AUTOSAR XML (schema 00044)
package /ComponentTypes
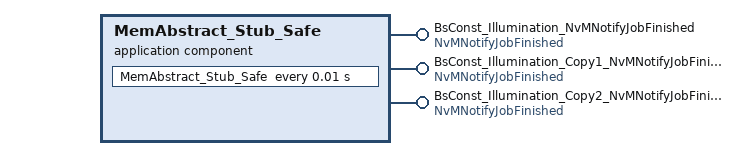
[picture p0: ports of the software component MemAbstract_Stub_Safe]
  application sw component type MemAbstract_Stub_Safe
    11 x provide/require port, all with nv-provide-com-spec=Value, nv-require-com-spec=Value:
      BsConst_BsConst_Illumination_ReservedByte: provided-required-interface=BsConst_BsConst_Illumination_ReservedByte
      BsConst_Compensation_Line_Shift_b: provided-required-interface=BsConst_Compensation_Line_Shift_b
      BsConst_Compensation_Line_Slope_m: provided-required-interface=BsConst_Compensation_Line_Slope_m
      BsConst_Derating_Backlight_Disable: provided-required-interface=BsConst_Derating_Backlight_Disable
      BsConst_Display_Illum_Max_Level_Safe: provided-required-interface=BsConst_Display_Illum_Max_Level
      BsConst_Lookup_Curve_HotSpot_Coef_X: provided-required-interface=BsConst_Lookup_Curve_HotSpot_Coef_X
      BsConst_Lookup_Curve_HotSpot_Coef_Y: provided-required-interface=BsConst_Lookup_Curve_HotSpot_Coef_Y
      BsConst_PCB_Temperature_Sensor_Conv: provided-required-interface=BsConst_PCB_Temperature_Sensor_Conv
      BsConst_PWM_boost_bypass_duty: provided-required-interface=BsConst_PWM_boost_bypass_duty
      BsConst_Temp_Threshold_Hysteresis_Derating: provided-required-interface=BsConst_Temp_Threshold_Hysteresis_Derating
      BsConst_Temperature_Sensor_Conv: provided-required-interface=BsConst_Temperature_Sensor_Conv
    provide port BsConst_Illumination_NvMNotifyJobFinished: server-com-spec{operation=JobFinished, queue-length=1}, provided-interface=NvMNotifyJobFinished
    provide port BsConst_Illumination_Copy1_NvMNotifyJobFinished: server-com-spec{operation=JobFinished, queue-length=1}, provided-interface=NvMNotifyJobFinished
    provide port BsConst_Illumination_Copy2_NvMNotifyJobFinished: server-com-spec{operation=JobFinished, queue-length=1}, provided-interface=NvMNotifyJobFinished
    behavior MemAbstract_Stub_Safe_InternalBehavior
      timing event TMT_MemAbstract_Stub_Safe: start-on-event=MemAbstract_Stub_Safe, period=0.01
      operation invoked event OIT_BsConst_Illumination_NvMNotifyJobFinished_JobFinished_BsConst_Illumination_NvMNotifyJobFinished_JobFinished: start-on-event=MemAbstractMdl_Safe_NotifyJobEnd_BsConst_Illumination, operation=BsConst_Illumination_NvMNotifyJobFinished.JobFinished
      operation invoked event OIT_BsConst_Illumination_Copy1_NvMNotifyJobFinished_JobFinished_BsConst_Illumination_Copy1_NvMNotifyJobFinished_JobFinished: start-on-event=MemAbstractMdl_Safe_NotifyJobEnd_BsConst_Illumination_Copy1, operation=BsConst_Illumination_Copy1_NvMNotifyJobFinished.JobFinished
      operation invoked event OIT_BsConst_Illumination_Copy2_NvMNotifyJobFinished_JobFinished_BsConst_Illumination_Copy2_NvMNotifyJobFinished_JobFinished: start-on-event=MemAbstractMdl_Safe_NotifyJobEnd_BsConst_Illumination_Copy2, operation=BsConst_Illumination_Copy2_NvMNotifyJobFinished.JobFinished
      4 x runnable:
        MemAbstract_Stub_Safe
          data-receive-point-by-arguments:
            11 x access:
              REC_BsConst_BsConst_Illumination_ReservedByte_Value: accessed-variable=BsConst_BsConst_Illumination_ReservedByte.Value
              REC_BsConst_Compensation_Line_Shift_b_Value: accessed-variable=BsConst_Compensation_Line_Shift_b.Value
              REC_BsConst_Compensation_Line_Slope_m_Value: accessed-variable=BsConst_Compensation_Line_Slope_m.Value
              REC_BsConst_Derating_Backlight_Disable_Value: accessed-variable=BsConst_Derating_Backlight_Disable.Value
              REC_BsConst_Display_Illum_Max_Level_Safe_Value: accessed-variable=BsConst_Display_Illum_Max_Level_Safe.Value
              REC_BsConst_Lookup_Curve_HotSpot_Coef_X_Value: accessed-variable=BsConst_Lookup_Curve_HotSpot_Coef_X.Value
              REC_BsConst_Lookup_Curve_HotSpot_Coef_Y_Value: accessed-variable=BsConst_Lookup_Curve_HotSpot_Coef_Y.Value
              REC_BsConst_PCB_Temperature_Sensor_Conv_Value: accessed-variable=BsConst_PCB_Temperature_Sensor_Conv.Value
              REC_BsConst_PWM_boost_bypass_duty_Value: accessed-variable=BsConst_PWM_boost_bypass_duty.Value
              REC_BsConst_Temp_Threshold_Hysteresis_Derating_Value: accessed-variable=BsConst_Temp_Threshold_Hysteresis_Derating.Value
              REC_BsConst_Temperature_Sensor_Conv_Value: accessed-variable=BsConst_Temperature_Sensor_Conv.Value
          data-send-points:
            11 x access:
              SEND_BsConst_BsConst_Illumination_ReservedByte_Value: accessed-variable=BsConst_BsConst_Illumination_ReservedByte.Value
              SEND_BsConst_Compensation_Line_Shift_b_Value: accessed-variable=BsConst_Compensation_Line_Shift_b.Value
              SEND_BsConst_Compensation_Line_Slope_m_Value: accessed-variable=BsConst_Compensation_Line_Slope_m.Value
              SEND_BsConst_Derating_Backlight_Disable_Value: accessed-variable=BsConst_Derating_Backlight_Disable.Value
              SEND_BsConst_Display_Illum_Max_Level_Safe_Value: accessed-variable=BsConst_Display_Illum_Max_Level_Safe.Value
              SEND_BsConst_Lookup_Curve_HotSpot_Coef_X_Value: accessed-variable=BsConst_Lookup_Curve_HotSpot_Coef_X.Value
              SEND_BsConst_Lookup_Curve_HotSpot_Coef_Y_Value: accessed-variable=BsConst_Lookup_Curve_HotSpot_Coef_Y.Value
              SEND_BsConst_PCB_Temperature_Sensor_Conv_Value: accessed-variable=BsConst_PCB_Temperature_Sensor_Conv.Value
              SEND_BsConst_PWM_boost_bypass_duty_Value: accessed-variable=BsConst_PWM_boost_bypass_duty.Value
              SEND_BsConst_Temp_Threshold_Hysteresis_Derating_Value: accessed-variable=BsConst_Temp_Threshold_Hysteresis_Derating.Value
              SEND_BsConst_Temperature_Sensor_Conv_Value: accessed-variable=BsConst_Temperature_Sensor_Conv.Value
        MemAbstractMdl_Safe_NotifyJobEnd_BsConst_Illumination
        MemAbstractMdl_Safe_NotifyJobEnd_BsConst_Illumination_Copy1
        MemAbstractMdl_Safe_NotifyJobEnd_BsConst_Illumination_Copy2
  swc implementation MemAbstract_Stub_Safe_Implementation: behavior=MemAbstract_Stub_Safe_InternalBehavior
    code-descriptors:
      code Default: artifact-descriptors=autosar-engineering-object=category=SWSRC
